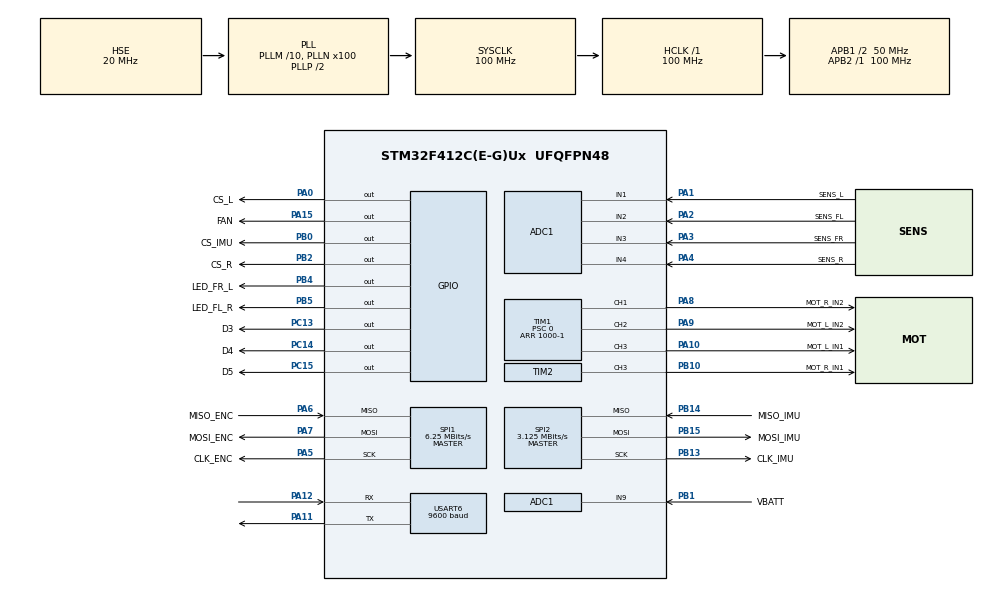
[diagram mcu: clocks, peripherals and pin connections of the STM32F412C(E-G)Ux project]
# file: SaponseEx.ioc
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ADC1.Channel-0\#ChannelRegularConversion=ADC_CHANNEL_9
ADC1.ClockPrescaler=ADC_CLOCK_SYNC_PCLK_DIV4
ADC1.ContinuousConvMode=DISABLE
ADC1.DMAContinuousRequests=DISABLE
ADC1.DiscontinuousConvMode=ENABLE
ADC1.EOCSelection=ADC_EOC_SEQ_CONV
ADC1.ExternalTrigConv=ADC_SOFTWARE_START
ADC1.InjNumberOfConversion=0
ADC1.NbrOfConversion=1
ADC1.NbrOfConversionFlag=1
ADC1.Rank-0\#ChannelRegularConversion=1
ADC1.SamplingTime-0\#ChannelRegularConversion=ADC_SAMPLETIME_56CYCLES
ADC1.ScanConvMode=ENABLE
ADC1.master=1
Mcu.Family=STM32F4
Mcu.Name=STM32F412C(E-G)Ux
Mcu.Package=UFQFPN48
NVIC.PriorityGroup=NVIC_PRIORITYGROUP_4
NVIC.TIM1_TRG_COM_TIM11_IRQn=true\:0\:0\:false\:false\:true\:true\:true\:true
NVIC.TIM1_UP_TIM10_IRQn=true\:0\:0\:false\:false\:true\:true\:true\:true
NVIC.TIM6_IRQn=true\:0\:0\:false\:false\:true\:true\:true\:true
NVIC.TIM7_IRQn=true\:0\:0\:false\:false\:true\:true\:true\:true
PA0.GPIO_Label=CS_L
PA0.Signal=GPIO_Output
PA1.GPIO_Label=SENS_L
PA1.Signal=ADCx_IN1
PA10.GPIO_Label=MOT_L_IN1
PA10.Signal=S_TIM1_CH3
PA11.Mode=Asynchronous
PA11.Signal=USART6_TX
PA12.Mode=Asynchronous
PA12.Signal=USART6_RX
PA13.Mode=Trace_Asynchronous_SW
PA13.Signal=SYS_JTMS-SWDIO
PA14.Mode=Trace_Asynchronous_SW
PA14.Signal=SYS_JTCK-SWCLK
PA15.GPIO_Label=FAN
PA15.Signal=GPIO_Output
PA2.GPIO_Label=SENS_FL
PA2.Signal=ADCx_IN2
PA3.GPIO_Label=SENS_FR
PA3.Signal=ADCx_IN3
PA4.GPIO_Label=SENS_R
PA4.Signal=ADCx_IN4
PA5.GPIO_Label=CLK_ENC
PA5.Mode=Full_Duplex_Master
PA5.Signal=SPI1_SCK
PA6.GPIO_Label=MISO_ENC
PA6.Mode=Full_Duplex_Master
PA6.Signal=SPI1_MISO
PA7.GPIO_Label=MOSI_ENC
PA7.Mode=Full_Duplex_Master
PA7.Signal=SPI1_MOSI
PA8.GPIO_Label=MOT_R_IN2
PA8.Signal=S_TIM1_CH1
PA9.GPIO_Label=MOT_L_IN2
PA9.Signal=S_TIM1_CH2
PB0.GPIO_Label=CS_IMU
PB0.Signal=GPIO_Output
PB1.GPIO_Label=VBATT
PB1.Signal=ADCx_IN9
PB10.GPIO_Label=MOT_R_IN1
PB10.Signal=S_TIM2_CH3
PB13.GPIO_Label=CLK_IMU
PB13.Mode=Full_Duplex_Master
PB13.Signal=SPI2_SCK
PB14.GPIO_Label=MISO_IMU
PB14.Mode=Full_Duplex_Master
PB14.Signal=SPI2_MISO
PB15.GPIO_Label=MOSI_IMU
PB15.Mode=Full_Duplex_Master
PB15.Signal=SPI2_MOSI
PB2.GPIO_Label=CS_R
PB2.Signal=GPIO_Output
PB3.Mode=Trace_Asynchronous_SW
PB3.Signal=SYS_JTDO-SWO
PB4.GPIO_Label=LED_FR_L
PB4.Signal=GPIO_Output
PB5.GPIO_Label=LED_FL_R
PB5.Signal=GPIO_Output
PC13.GPIO_Label=D3
PC13.Signal=GPIO_Output
PC14-OSC32_IN.GPIO_Label=D4
PC14-OSC32_IN.PinState=GPIO_PIN_RESET
PC14-OSC32_IN.Signal=GPIO_Output
PC15-OSC32_OUT.GPIO_Label=D5
PC15-OSC32_OUT.Signal=GPIO_Output
PH0\ -\ OSC_IN.Mode=HSE-External-Clock-Source
PH0\ -\ OSC_IN.Signal=RCC_OSC_IN
PH1\ -\ OSC_OUT.Mode=HSE-External-Clock-Source
PH1\ -\ OSC_OUT.Signal=RCC_OSC_OUT
ProjectManager.HeapSize=0x200
ProjectManager.StackSize=0x400
ProjectManager.TargetToolchain=Makefile
RCC.AHBFreq_Value=100000000
RCC.APB1CLKDivider=RCC_HCLK_DIV2
RCC.APB1Freq_Value=50000000
RCC.APB1TimFreq_Value=100000000
RCC.APB2Freq_Value=100000000
RCC.APB2TimFreq_Value=100000000
RCC.CortexFreq_Value=100000000
RCC.HCLKFreq_Value=100000000
RCC.HSE_VALUE=20000000
RCC.PLLI2SM=2
RCC.PLLI2SN=50
RCC.PLLM=10
RCC.PLLN=100
RCC.PLLSourceVirtual=RCC_PLLSOURCE_HSE
RCC.SYSCLKFreq_VALUE=100000000
RCC.SYSCLKSource=RCC_SYSCLKSOURCE_PLLCLK
RCC.USBFreq_Value=100000000
RCC.VCOOutputFreq_Value=200000000
SH.ADCx_IN1.0=ADC1_IN1,IN1
SH.ADCx_IN2.0=ADC1_IN2,IN2
SH.ADCx_IN3.0=ADC1_IN3,IN3
SH.ADCx_IN4.0=ADC1_IN4,IN4
SH.ADCx_IN9.0=ADC1_IN9,IN9
SH.S_TIM1_CH1.0=TIM1_CH1,PWM Generation1 CH1
SH.S_TIM1_CH2.0=TIM1_CH2,PWM Generation2 CH2
SH.S_TIM1_CH3.0=TIM1_CH3,PWM Generation3 CH3
SH.S_TIM2_CH3.0=TIM2_CH3,PWM Generation3 CH3
SPI1.BaudRatePrescaler=SPI_BAUDRATEPRESCALER_16
SPI1.CLKPhase=SPI_PHASE_2EDGE
SPI1.CalculateBaudRate=6.25 MBits/s
SPI1.DataSize=SPI_DATASIZE_16BIT
SPI1.Direction=SPI_DIRECTION_2LINES
SPI1.Mode=SPI_MODE_MASTER
SPI1.VirtualType=VM_MASTER
SPI2.BaudRatePrescaler=SPI_BAUDRATEPRESCALER_16
SPI2.CLKPhase=SPI_PHASE_2EDGE
SPI2.CLKPolarity=SPI_POLARITY_HIGH
SPI2.CalculateBaudRate=3.125 MBits/s
SPI2.Direction=SPI_DIRECTION_2LINES
SPI2.Mode=SPI_MODE_MASTER
SPI2.VirtualType=VM_MASTER
STMicroelectronics.X-CUBE-ALGOBUILD.1.3.0.LibraryCcDSPOoLibraryJjDSPOoLibrary=true
TIM1.Channel-PWM\ Generation1\ CH1=TIM_CHANNEL_1
TIM1.Channel-PWM\ Generation2\ CH2=TIM_CHANNEL_2
TIM1.Channel-PWM\ Generation3\ CH3=TIM_CHANNEL_3
TIM1.Period=1000-1
TIM1.Prescaler=0
TIM2.Channel-PWM\ Generation3\ CH3=TIM_CHANNEL_3
TIM2.Period=1000-1
TIM2.Prescaler=0
TIM6.AutoReloadPreload=TIM_AUTORELOAD_PRELOAD_ENABLE
TIM6.Period=1000-1
TIM6.Prescaler=100-1
TIM7.Period=500-1
TIM7.Prescaler=100-1
USART6.BaudRate=9600
USART6.VirtualMode=VM_ASYNC
VP_STMicroelectronics.X-CUBE-ALGOBUILD_VS_DSPOoLibraryJjLibrary_1.3.0_1.3.0.Mode=DSPOoLibraryJjLibrary
VP_TIM6_VS_ClockSourceINT.Mode=Enable_Timer
VP_TIM7_VS_ClockSourceINT.Mode=Enable_Timer
board=custom

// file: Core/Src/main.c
/* USER CODE BEGIN Header */
/**
  ******************************************************************************
  * @file           : main.c
  * @brief          : Main program body
  ******************************************************************************
  * @attention
  *
  * Copyright (c) 2023 STMicroelectronics.
  * All rights reserved.
  *
  * This software is licensed under terms that can be found in the LICENSE file
  * in the root directory of this software component.
  * If no LICENSE file comes with this software, it is provided AS-IS.
  *
  ******************************************************************************
  */
/* USER CODE END Header */
#include "main.h"
#include "adc.h"
#include "spi.h"
#include "tim.h"
#include "usart.h"
#include "gpio.h"

void SystemClock_Config(void);

int main(void)
{

  /* MCU Configuration--------------------------------------------------------*/

  /* Reset of all peripherals, Initializes the Flash interface and the Systick. */
  HAL_Init();

  /* Configure the system clock */
  SystemClock_Config();

  /* Initialize all configured peripherals */
  MX_GPIO_Init();
  MX_SPI2_Init();
  MX_ADC1_Init();
  MX_SPI1_Init();
  MX_TIM1_Init();
  MX_TIM2_Init();
  MX_TIM6_Init();
  MX_USART6_UART_Init();
  MX_TIM7_Init();
  /* USER CODE BEGIN 2 */
  system_init();

  /* USER CODE END 2 */

  /* Infinite loop */
  while (1)
  {

  }
}

void SystemClock_Config(void)
{
  RCC_OscInitTypeDef RCC_OscInitStruct = {0};
  RCC_ClkInitTypeDef RCC_ClkInitStruct = {0};

  /** Configure the main internal regulator output voltage
  */
  __HAL_RCC_PWR_CLK_ENABLE();
  __HAL_PWR_VOLTAGESCALING_CONFIG(PWR_REGULATOR_VOLTAGE_SCALE1);

  /** Initializes the RCC Oscillators according to the specified parameters
  * in the RCC_OscInitTypeDef structure.
  */
  RCC_OscInitStruct.OscillatorType = RCC_OSCILLATORTYPE_HSE;
  RCC_OscInitStruct.HSEState = RCC_HSE_BYPASS;
  RCC_OscInitStruct.PLL.PLLState = RCC_PLL_ON;
  RCC_OscInitStruct.PLL.PLLSource = RCC_PLLSOURCE_HSE;
  RCC_OscInitStruct.PLL.PLLM = 10;
  RCC_OscInitStruct.PLL.PLLN = 100;
  RCC_OscInitStruct.PLL.PLLP = RCC_PLLP_DIV2;
  RCC_OscInitStruct.PLL.PLLQ = 2;
  RCC_OscInitStruct.PLL.PLLR = 2;
  if (HAL_RCC_OscConfig(&RCC_OscInitStruct) != HAL_OK)
  {
    Error_Handler();
  }

  /** Initializes the CPU, AHB and APB buses clocks
  */
  RCC_ClkInitStruct.ClockType = RCC_CLOCKTYPE_HCLK|RCC_CLOCKTYPE_SYSCLK
                              |RCC_CLOCKTYPE_PCLK1|RCC_CLOCKTYPE_PCLK2;
  RCC_ClkInitStruct.SYSCLKSource = RCC_SYSCLKSOURCE_PLLCLK;
  RCC_ClkInitStruct.AHBCLKDivider = RCC_SYSCLK_DIV1;
  RCC_ClkInitStruct.APB1CLKDivider = RCC_HCLK_DIV2;
  RCC_ClkInitStruct.APB2CLKDivider = RCC_HCLK_DIV1;

  if (HAL_RCC_ClockConfig(&RCC_ClkInitStruct, FLASH_LATENCY_3) != HAL_OK)
  {
    Error_Handler();
  }
}

/* USER CODE BEGIN 4 */
int _write(int file, char *ptr, int len)
{
  int DataIdx;
  for(DataIdx=0; DataIdx<len; DataIdx++)
  {
    ITM_SendChar(*ptr++,0);
  }
  return len;
}
void HAL_TIM_PeriodElapsedCallback(TIM_HandleTypeDef *htim)
{
  if(htim->Instance == TIM6){
    interrupt_1ms();
  }
  if(htim->Instance == TIM7){
    interrupt_500us();
  }
}
/* USER CODE END 4 */

void Error_Handler(void)
{
  __disable_irq();
  while (1)
  {
  }
}
